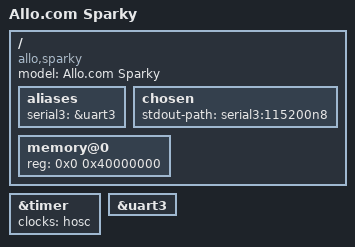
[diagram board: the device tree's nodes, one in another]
/dts-v1/;
#include "owl-s500.dtsi"
/ {
	compatible = "allo,sparky", "actions,s500";
	model = "Allo.com Sparky";
	aliases {
		serial3 = &uart3;
	};
	chosen {
		stdout-path = "serial3:115200n8";
	};
	memory@0 {
		device_type = "memory";
		reg = <0x0 0x40000000>;  
	};
};
&timer {
	clocks = <&hosc>;
};
&uart3 {
	status = "okay";
};
